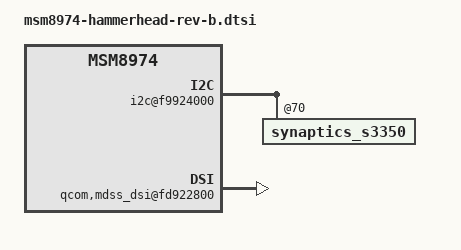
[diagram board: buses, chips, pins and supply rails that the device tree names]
/* Copyright (c) 2013, LGE Inc. All rights reserved.
 * Copyright (c) 2012, Code Aurora Forum. All rights reserved.
 *
 * This program is free software; you can redistribute it and/or modify
 * it under the terms of the GNU General Public License version 2 and
 * only version 2 as published by the Free Software Foundation.
 *
 * This program is distributed in the hope that it will be useful,
 * but WITHOUT ANY WARRANTY; without even the implied warranty of
 * MERCHANTABILITY or FITNESS FOR A PARTICULAR PURPOSE.  See the
 * GNU General Public License for more details.
 */

/include/ "msm8974-hammerhead.dtsi"

&soc {
	i2c@f9924000 {
		synaptics_s3350@70 {
			status = "ok";
			synaptics,type = <1>;
		};
	};

	vibrator {
		vdd-supply = <&pm8941_l19>;
		use-vdd-supply;
		vibe-warmup-delay = <25>;
	};

	qcom,mdss_dsi@fd922800 {
                qcom,platform-regulator-settings = [
                        03 01 01 00  /* Regualotor settings */
                        20 00 01];
                qcom,platform-strength-ctrl = [
                        bb 06];
                qcom,platform-bist-ctrl = [
                        00 00 b1 ff           /* BIST Ctrl settings */
                        00 00];
                qcom,platform-lane-config = [
                        00 c2 45 00 00 00 00 01 75 /* lane0 config */
                        00 c2 45 00 00 00 00 01 75 /* lane1 config */
                        00 c2 45 00 00 00 00 01 75 /* lane2 config */
                        00 c2 45 00 00 00 00 01 75 /* lane3 config */
                        00 02 45 00 00 00 00 01 97]; /* Clk ln config */
		status = "ok";
		
                qcom,dsi-pref-prim-pan = <&dsi_jdi_command_ors>;
        };
};
